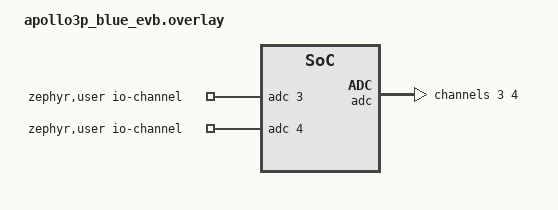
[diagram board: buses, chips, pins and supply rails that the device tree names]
/*
 * Copyright (c) 2024 Semios Inc
 *
 * SPDX-License-Identifier: Apache-2.0
 */

/ {
	zephyr,user {
		/* adjust channel number according to pinmux in board.dts */
		io-channels = <&adc 3>, <&adc 4>;
	};
};

&adc_default {
	group1 {
		pinmux = <ADCSE3_P31>, <ADCSE4_P32>;
	};
};

&adc {
	#address-cells = <1>;
	#size-cells = <0>;
	status = "okay";

	channel@3 {
		reg = <3>;
		zephyr,gain = "ADC_GAIN_1";
		zephyr,reference = "ADC_REF_INTERNAL";
		zephyr,acquisition-time = <ADC_ACQ_TIME_DEFAULT>;
		zephyr,resolution = <12>;
	};

	channel@4 {
		reg = <4>;
		zephyr,gain = "ADC_GAIN_1";
		zephyr,reference = "ADC_REF_INTERNAL";
		zephyr,acquisition-time = <ADC_ACQ_TIME_DEFAULT>;
		zephyr,resolution = <12>;
	};
};
